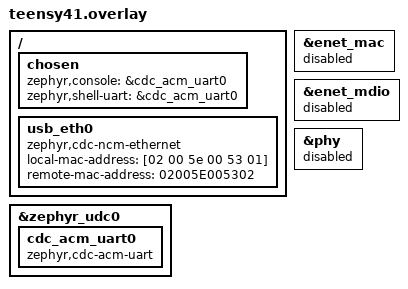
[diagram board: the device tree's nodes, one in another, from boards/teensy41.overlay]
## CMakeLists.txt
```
# SPDX-License-Identifier: Apache-2.0
cmake_minimum_required(VERSION 3.20.0)
find_package(Zephyr REQUIRED HINTS $ENV{ZEPHYR_BASE})
project(usb_udp_echo)

target_sources(app PRIVATE src/main.c src/usb.c)
target_sources_ifdef(CONFIG_BOARD_TEENSY41 app PRIVATE src/teensy_bootloader.c)

# Placement (README.md). Whole libraries and files by Kconfig; or a list of hot functions by name
# (-DCODEPLACE_LIST=<file.cmake>, made by "python -m codeplace pick"; needs CONFIG_CODE_DATA_RELOCATION=y).
if(CONFIG_SAMPLE_HOT_PATH_LIBS)
  foreach(lib subsys__net__ip subsys__net subsys__net__l2__ethernet lib__net_buf
          subsys__usb__device_next drivers__usb__udc)
    zephyr_code_relocate(LIBRARY ${lib} LOCATION ${CONFIG_SAMPLE_HOT_PATH_REGION}_TEXT NOKEEP)
  endforeach()
endif()
if(CONFIG_SAMPLE_HOT_PATH_FILES)
  include(${CMAKE_CURRENT_SOURCE_DIR}/placement/imxrt-hot-files.cmake)
endif()
if(DEFINED CODEPLACE_LIST)
  include(${CODEPLACE_LIST})
endif()
```

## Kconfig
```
# SPDX-License-Identifier: Apache-2.0

config SAMPLE_HOT_PATH_LIBS
	bool "Network and USB stack libraries in fast memory"
	select CODE_DATA_RELOCATION
	help
	  Relocates the network (IP, core, Ethernet L2, net_buf), USB device
	  stack and UDC driver libraries to SAMPLE_HOT_PATH_REGION, as
	  samples/net/zperf does.

config SAMPLE_HOT_PATH_FILES
	bool "Also kernel, arch and controller-driver files in fast memory (i.MX RT)"
	depends on SAMPLE_HOT_PATH_LIBS && SOC_SERIES_IMXRT10XX
	help
	  Adds the scheduler, work queue, timeouts, mutex/semaphore/queue,
	  context switch, MPU, SysTick, heap and the MCUX EHCI controller
	  driver (placement/imxrt-hot-files.cmake). Code that runs before the
	  relocation copy (SystemInit, memcpy, memset, reset) stays in flash.

config SAMPLE_HOT_PATH_REGION
	string "Memory region for the hot path"
	default "ITCM" if SOC_SERIES_IMXRT10XX
	default "RAM"
	help
	  Zephyr memory region name for zephyr_code_relocate(): ITCM on
	  i.MX RT, RAM (SRAM) on the RP2040.

source "Kconfig.zephyr"
```

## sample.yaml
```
sample:
  name: USB UDP echo (code placement benchmark)
  description: UDP echo over USB CDC-NCM/ECM; hot path in fast memory by Kconfig or by a function list
common:
  tags: usb net codeplace
  build_only: true
  platform_allow:
    - teensy41
    - rpi_pico
tests:
  codeplace.usb_udp_echo.stock: {}
  codeplace.usb_udp_echo.hot_path:
    extra_conf_files:
      - placement/hot-path.conf
  codeplace.usb_udp_echo.fast:
    platform_allow:
      - teensy41
    extra_conf_files:
      - placement/hot-path.conf
      - placement/tuning.conf
  codeplace.usb_udp_echo.pc_sampler:
    platform_allow:
      - teensy41
    extra_conf_files:
      - placement/hot-path.conf
      - placement/pc-sampler.conf
```

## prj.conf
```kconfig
# UDP echo over USB (zephyr-codeplace benchmark workload)
CONFIG_USB_DEVICE_STACK_NEXT=y
CONFIG_HWINFO=y

CONFIG_NETWORKING=y
CONFIG_NET_L2_ETHERNET=y
CONFIG_NET_IPV4=y
CONFIG_NET_IPV6=n
CONFIG_NET_TCP=n
CONFIG_NET_UDP=y
CONFIG_NET_SOCKETS=y
CONFIG_NET_DHCPV4=n
CONFIG_NET_IPV4_IGMP=n
CONFIG_NET_IPV4_ACD=n
CONFIG_NET_IPV4_AUTO=n
CONFIG_NET_CONNECTION_MANAGER=n
CONFIG_NET_CONFIG_SETTINGS=n
CONFIG_NET_MAX_CONTEXTS=2
CONFIG_NET_TC_RX_COUNT=1
CONFIG_NET_TC_TX_COUNT=1
CONFIG_NET_PKT_RX_COUNT=8
CONFIG_NET_PKT_TX_COUNT=8
CONFIG_NET_BUF_RX_COUNT=32
CONFIG_NET_BUF_TX_COUNT=32
CONFIG_NET_LOG=n

CONFIG_LOG=y
CONFIG_LOG_MODE_DEFERRED=y
CONFIG_PRINTK=y
```

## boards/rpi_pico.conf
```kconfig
# No entropy driver for RP2040 in Zephyr; the NCM class needs sys_rand_get(). Not secure.
CONFIG_TEST_RANDOM_GENERATOR=y
```

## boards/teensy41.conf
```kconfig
# Shell on the USB CDC ACM console; "bootloader" enters HalfKay for flashing.
CONFIG_SERIAL=y
CONFIG_CONSOLE=y
CONFIG_UART_CONSOLE=y
CONFIG_UART_LINE_CTRL=y
CONFIG_CDC_ACM_SERIAL_INITIALIZE_AT_BOOT=n
CONFIG_SHELL=y
```

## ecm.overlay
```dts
/* CDC-ECM instead of CDC-NCM (-DEXTRA_DTC_OVERLAY_FILE=ecm.overlay). */
&usb_eth0 {
	compatible = "zephyr,cdc-ecm-ethernet";
};
```

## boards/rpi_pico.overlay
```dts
/* Console on UART0. */
/ {
	usb_eth0: usb_eth0 {
		compatible = "zephyr,cdc-ncm-ethernet";
		local-mac-address = [02 00 5e 00 53 01];
		remote-mac-address = "02005E005302";
	};
};
```

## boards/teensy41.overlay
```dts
/* Console and shell on USB CDC ACM, in the same USB device as CDC-NCM. */
/ {
	chosen {
		zephyr,console = &cdc_acm_uart0;
		zephyr,shell-uart = &cdc_acm_uart0;
	};

	usb_eth0: usb_eth0 {
		compatible = "zephyr,cdc-ncm-ethernet";
		local-mac-address = [02 00 5e 00 53 01];
		remote-mac-address = "02005E005302";
	};
};

&zephyr_udc0 {
	cdc_acm_uart0: cdc_acm_uart0 {
		compatible = "zephyr,cdc-acm-uart";
	};
};

&enet_mac { status = "disabled"; };
&enet_mdio { status = "disabled"; };
&phy { status = "disabled"; };
```

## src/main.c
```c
/*
 * SPDX-License-Identifier: Apache-2.0
 *
 * UDP echo over USB CDC-NCM (or CDC-ECM with ecm.overlay): the benchmark workload of
 * zephyr-codeplace. The board has the address 192.0.2.1/24 and echoes every UDP datagram
 * that arrives on port 4242. The placement of the code is chosen at build time (README.md).
 */

#include <zephyr/kernel.h>
#include <zephyr/net/net_if.h>
#include <zephyr/net/socket.h>

#define UDP_PORT 4242

int sample_usb_enable(void);

static uint8_t buf[1500];

int main(void)
{
	struct net_sockaddr_in addr = {
		.sin_family = NET_AF_INET,
		.sin_port = net_htons(UDP_PORT),
	};
	struct net_if *iface = net_if_lookup_by_dev(DEVICE_DT_GET(DT_NODELABEL(usb_eth0)));
	struct net_in_addr ip, mask;
	int sock, err;

	net_addr_pton(NET_AF_INET, "192.0.2.1", &ip);
	net_addr_pton(NET_AF_INET, "255.255.255.0", &mask);
	net_if_ipv4_addr_add(iface, &ip, NET_ADDR_MANUAL, 0);
	net_if_ipv4_set_netmask_by_addr(iface, &ip, &mask);

	err = sample_usb_enable();
	if (err != 0) {
		printk("usb enable failed: %d\n", err);
		return 0;
	}

	sock = zsock_socket(NET_AF_INET, NET_SOCK_DGRAM, NET_IPPROTO_UDP);
	if (sock < 0 || zsock_bind(sock, (struct net_sockaddr *)&addr, sizeof(addr)) != 0) {
		printk("socket setup failed\n");
		return 0;
	}
	printk("UDP echo on 192.0.2.1:%d\n", UDP_PORT);

	for (;;) {
		struct net_sockaddr_in from;
		net_socklen_t fromlen = sizeof(from);
		ssize_t n = zsock_recvfrom(sock, buf, sizeof(buf), 0, (struct net_sockaddr *)&from, &fromlen);

		if (n > 0) {
			(void)zsock_sendto(sock, buf, n, 0, (struct net_sockaddr *)&from, fromlen);
		}
	}

	return 0;
}
```

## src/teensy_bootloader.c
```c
/*
 * SPDX-License-Identifier: Apache-2.0
 */

#include <zephyr/kernel.h>
#include <zephyr/shell/shell.h>

/* PJRC "bkpt #251": the Teensy 4.1 ROM enters the HalfKay bootloader. */
static int cmd_bootloader(const struct shell *sh, size_t argc, char **argv)
{
	shell_print(sh, "Entering HalfKay");
	k_msleep(100);
	__asm__ volatile("bkpt #251" ::: "memory");

	return 0;
}

SHELL_CMD_ARG_REGISTER(bootloader, NULL, "Enter Teensy HalfKay bootloader", cmd_bootloader, 1, 0);
```

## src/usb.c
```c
/*
 * SPDX-License-Identifier: Apache-2.0
 *
 * USB device: CDC-NCM (or CDC-ECM with ecm.overlay), and CDC ACM when the
 * board puts the console on USB.
 */

#include <zephyr/kernel.h>
#include <zephyr/device.h>
#include <zephyr/usb/usbd.h>

#define ETH_CLASS COND_CODE_1(DT_HAS_COMPAT_STATUS_OKAY(zephyr_cdc_ecm_ethernet), \
			      ("cdc_ecm_0"), ("cdc_ncm_0"))

USBD_DEVICE_DEFINE(sample_usbd, DEVICE_DT_GET(DT_NODELABEL(zephyr_udc0)), 0x2fe3, 0x0005);

USBD_DESC_LANG_DEFINE(sample_lang);
USBD_DESC_MANUFACTURER_DEFINE(sample_mfr, "Zephyr Project");
USBD_DESC_PRODUCT_DEFINE(sample_product, "codeplace UDP echo");
USBD_DESC_SERIAL_NUMBER_DEFINE(sample_sn);

USBD_CONFIGURATION_DEFINE(sample_fs_config, 0, 125, NULL);
USBD_CONFIGURATION_DEFINE(sample_hs_config, 0, 125, NULL);

static int add_config(struct usbd_context *ctx, enum usbd_speed speed)
{
	struct usbd_config_node *cfg = (speed == USBD_SPEED_HS) ? &sample_hs_config : &sample_fs_config;
	int err;

	err = usbd_add_configuration(ctx, speed, cfg);
	if (err == 0 && DT_HAS_COMPAT_STATUS_OKAY(zephyr_cdc_acm_uart)) {
		err = usbd_register_class(ctx, "cdc_acm_0", speed, 1);
	}
	if (err == 0) {
		err = usbd_register_class(ctx, ETH_CLASS, speed, 1);
	}
	if (err == 0) {
		err = usbd_device_set_code_triple(ctx, speed, USB_BCC_MISCELLANEOUS, 0x02, 0x01);
	}

	return err;
}

int sample_usb_enable(void)
{
	int err;

	err = usbd_add_descriptor(&sample_usbd, &sample_lang);
	err = err ? err : usbd_add_descriptor(&sample_usbd, &sample_mfr);
	err = err ? err : usbd_add_descriptor(&sample_usbd, &sample_product);
	err = err ? err : usbd_add_descriptor(&sample_usbd, &sample_sn);

	if (err == 0 && USBD_SUPPORTS_HIGH_SPEED &&
	    usbd_caps_speed(&sample_usbd) == USBD_SPEED_HS) {
		err = add_config(&sample_usbd, USBD_SPEED_HS);
	}

	err = err ? err : add_config(&sample_usbd, USBD_SPEED_FS);
	err = err ? err : usbd_init(&sample_usbd);
	err = err ? err : usbd_enable(&sample_usbd);

	return err;
}
```
